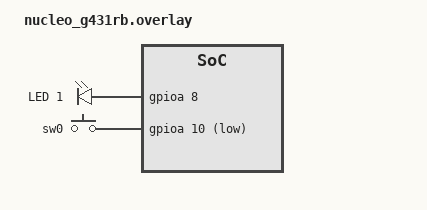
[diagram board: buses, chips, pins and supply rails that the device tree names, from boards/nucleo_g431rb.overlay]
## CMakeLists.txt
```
cmake_minimum_required(VERSION 3.20.0)

set(BOARD stm32f3_disco)

set(CONF_FILE "boards/stm32f3_disco.conf")
list(APPEND CONF_FILE "boards/stm32f3_disco.conf")

find_package(Zephyr REQUIRED HINTS $ENV{ZEPHYR_BASE})
project(se28cp_app)

target_sources(app PRIVATE 
    src/main.h 
    src/led.h 
    src/status.c 
    src/keyboard.h
    src/keyboard.c
    src/adc.c
    src/zbus.c
    src/main.c 
   
)
```

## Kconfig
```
source "Kconfig.zephyr"
config APP_WITH_STM32_HAL
    default y
    bool
    select USE_STM32_HAL_GPIO
    select USE_STM32_HAL_ADC
    select USE_STM32_HAL_ADC_EX
    select USE_STM32_HAL_DAC
    select USE_STM32_HAL_DAC_EX
    select USE_STM32_HAL_DMA
    select USE_STM32_HAL_DMA_EX
    select USE_STM32_HAL_CORTEX
    select USE_STM32_HAL_TIM
    select USE_STM32_HAL_TIM_EX
```

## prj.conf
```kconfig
CONFIG_ASSERT=y
CONFIG_GPIO=y
CONFIG_SHELL=y
```

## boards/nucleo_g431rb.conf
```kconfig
# Misc
CONFIG_HEAP_MEM_POOL_SIZE=8192
CONFIG_SHELL_STACK_SIZE=4096
#CONFIG_SYS_CLOCK_TICKS_PER_SEC=1

# Enable Shell
CONFIG_SHELL=y

# Setting the Shell prompt
CONFIG_SHELL_PROMPT_UART="patchon$ "

# Setting the max argc
CONFIG_SHELL_ARGC_MAX=12

# Enable the Zephyr boot banner
CONFIG_BOOT_BANNER=y

CONFIG_THREAD_RUNTIME_STATS=y

CONFIG_SYS_CLOCK_TICKS_PER_SEC=1000
```

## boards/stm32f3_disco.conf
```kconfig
# Misc
CONFIG_HEAP_MEM_POOL_SIZE=8192
CONFIG_SHELL_STACK_SIZE=4096
#CONFIG_SYS_CLOCK_TICKS_PER_SEC=1

# Enable Shell
CONFIG_SHELL=y

# Setting the Shell prompt
CONFIG_SHELL_PROMPT_UART="patchon$ "

# Setting the max argc
CONFIG_SHELL_ARGC_MAX=12

# Enable the Zephyr boot banner
CONFIG_BOOT_BANNER=y

CONFIG_THREAD_RUNTIME_STATS=y

CONFIG_SYS_CLOCK_TICKS_PER_SEC=1000

CONFIG_ZBUS=y
CONFIG_ZBUS_LOG_LEVEL_INF=y
CONFIG_ZBUS_CHANNEL_NAME=y
CONFIG_ZBUS_OBSERVER_NAME=y
CONFIG_ZBUS_RUNTIME_OBSERVERS=y

CONFIG_CMSIS_DSP=y
CONFIG_NEWLIB_LIBC=y
CONFIG_FPU=y
CONFIG_NEWLIB_LIBC_FLOAT_PRINTF=y
```

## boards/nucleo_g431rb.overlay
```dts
#include <zephyr/dt-bindings/gpio/gpio.h>

/ {
	aliases {
		led1 = &led1;
		sw0 = &sw0;
	};

	leds {
		compatible = "gpio-leds";
		led1: led_1 {
			gpios = <&gpioa 8 GPIO_ACTIVE_HIGH>;
			label = "LED 1";
		};
	};

	buttons {
		compatible = "gpio-keys";
		sw0: sw_0 {
			gpios = <&gpioa 10 (GPIO_PULL_UP | GPIO_ACTIVE_LOW)>;
			zephyr,code = <INPUT_KEY_1>;
		};
	};
};
```

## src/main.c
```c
#include "main.h"

int main(void)
{

	return 0;
}
```

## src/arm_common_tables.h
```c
/* ----------------------------------------------------------------------
 * Copyright (C) 2010-2014 ARM Limited. All rights reserved.
 *
 * $Date:        19. October 2015
 * $Revision: 	V.1.4.5 a
 *
 * Project: 	    CMSIS DSP Library
 * Title:	    arm_common_tables.h
 *
 * Description:	This file has extern declaration for common tables like Bitreverse, reciprocal etc
 * which are used across different functions
 *
 * Target Processor: Cortex-M4/Cortex-M3
 *
 * Redistribution and use in source and binary forms, with or without
 * modification, are permitted provided that the following conditions
 * are met:
 *   - Redistributions of source code must retain the above copyright
 *     notice, this list of conditions and the following disclaimer.
 *   - Redistributions in binary form must reproduce the above copyright
 *     notice, this list of conditions and the following disclaimer in
 *     the documentation and/or other materials provided with the
 *     distribution.
 *   - Neither the name of ARM LIMITED nor the names of its contributors
 *     may be used to endorse or promote products derived from this
 *     software without specific prior written permission.
 *
 * THIS SOFTWARE IS PROVIDED BY THE COPYRIGHT HOLDERS AND CONTRIBUTORS
 * "AS IS" AND ANY EXPRESS OR IMPLIED WARRANTIES, INCLUDING, BUT NOT
 * LIMITED TO, THE IMPLIED WARRANTIES OF MERCHANTABILITY AND FITNESS
 * FOR A PARTICULAR PURPOSE ARE DISCLAIMED. IN NO EVENT SHALL THE
 * COPYRIGHT OWNER OR CONTRIBUTORS BE LIABLE FOR ANY DIRECT, INDIRECT,
 * INCIDENTAL, SPECIAL, EXEMPLARY, OR CONSEQUENTIAL DAMAGES (INCLUDING,
 * BUT NOT LIMITED TO, PROCUREMENT OF SUBSTITUTE GOODS OR SERVICES;
 * LOSS OF USE, DATA, OR PROFITS; OR BUSINESS INTERRUPTION) HOWEVER
 * CAUSED AND ON ANY THEORY OF LIABILITY, WHETHER IN CONTRACT, STRICT
 * LIABILITY, OR TORT (INCLUDING NEGLIGENCE OR OTHERWISE) ARISING IN
 * ANY WAY OUT OF THE USE OF THIS SOFTWARE, EVEN IF ADVISED OF THE
 * POSSIBILITY OF SUCH DAMAGE.
 * -------------------------------------------------------------------- */

#ifndef _ARM_COMMON_TABLES_H
#define _ARM_COMMON_TABLES_H

#include "arm_math.h"

extern const uint16_t armBitRevTable[1024];
extern const q15_t armRecipTableQ15[64];
extern const q31_t armRecipTableQ31[64];
/* extern const q31_t realCoefAQ31[1024]; */
/* extern const q31_t realCoefBQ31[1024]; */
extern const float32_t twiddleCoef_16[32];
extern const float32_t twiddleCoef_32[64];
extern const float32_t twiddleCoef_64[128];
extern const float32_t twiddleCoef_128[256];
extern const float32_t twiddleCoef_256[512];
extern const float32_t twiddleCoef_512[1024];
extern const float32_t twiddleCoef_1024[2048];
extern const float32_t twiddleCoef_2048[4096];
extern const float32_t twiddleCoef_4096[8192];
#define twiddleCoef twiddleCoef_4096
extern const q31_t twiddleCoef_16_q31[24];
extern const q31_t twiddleCoef_32_q31[48];
extern const q31_t twiddleCoef_64_q31[96];
extern const q31_t twiddleCoef_128_q31[192];
extern const q31_t twiddleCoef_256_q31[384];
extern const q31_t twiddleCoef_512_q31[768];
extern const q31_t twiddleCoef_1024_q31[1536];
extern const q31_t twiddleCoef_2048_q31[3072];
extern const q31_t twiddleCoef_4096_q31[6144];
extern const q15_t twiddleCoef_16_q15[24];
extern const q15_t twiddleCoef_32_q15[48];
extern const q15_t twiddleCoef_64_q15[96];
extern const q15_t twiddleCoef_128_q15[192];
extern const q15_t twiddleCoef_256_q15[384];
extern const q15_t twiddleCoef_512_q15[768];
extern const q15_t twiddleCoef_1024_q15[1536];
extern const q15_t twiddleCoef_2048_q15[3072];
extern const q15_t twiddleCoef_4096_q15[6144];
extern const float32_t twiddleCoef_rfft_32[32];
extern const float32_t twiddleCoef_rfft_64[64];
extern const float32_t twiddleCoef_rfft_128[128];
extern const float32_t twiddleCoef_rfft_256[256];
extern const float32_t twiddleCoef_rfft_512[512];
extern const float32_t twiddleCoef_rfft_1024[1024];
extern const float32_t twiddleCoef_rfft_2048[2048];
extern const float32_t twiddleCoef_rfft_4096[4096];

/* floating-point bit reversal tables */
#define ARMBITREVINDEXTABLE__16_TABLE_LENGTH ((uint16_t)20)
#define ARMBITREVINDEXTABLE__32_TABLE_LENGTH ((uint16_t)48)
#define ARMBITREVINDEXTABLE__64_TABLE_LENGTH ((uint16_t)56)
#define ARMBITREVINDEXTABLE_128_TABLE_LENGTH ((uint16_t)208)
#define ARMBITREVINDEXTABLE_256_TABLE_LENGTH ((uint16_t)440)
#define ARMBITREVINDEXTABLE_512_TABLE_LENGTH ((uint16_t)448)
#define ARMBITREVINDEXTABLE1024_TABLE_LENGTH ((uint16_t)1800)
#define ARMBITREVINDEXTABLE2048_TABLE_LENGTH ((uint16_t)3808)
#define ARMBITREVINDEXTABLE4096_TABLE_LENGTH ((uint16_t)4032)

extern const uint16_t armBitRevIndexTable16[ARMBITREVINDEXTABLE__16_TABLE_LENGTH];
extern const uint16_t armBitRevIndexTable32[ARMBITREVINDEXTABLE__32_TABLE_LENGTH];
extern const uint16_t armBitRevIndexTable64[ARMBITREVINDEXTABLE__64_TABLE_LENGTH];
extern const uint16_t armBitRevIndexTable128[ARMBITREVINDEXTABLE_128_TABLE_LENGTH];
extern const uint16_t armBitRevIndexTable256[ARMBITREVINDEXTABLE_256_TABLE_LENGTH];
extern const uint16_t armBitRevIndexTable512[ARMBITREVINDEXTABLE_512_TABLE_LENGTH];
extern const uint16_t armBitRevIndexTable1024[ARMBITREVINDEXTABLE1024_TABLE_LENGTH];
extern const uint16_t armBitRevIndexTable2048[ARMBITREVINDEXTABLE2048_TABLE_LENGTH];
extern const uint16_t armBitRevIndexTable4096[ARMBITREVINDEXTABLE4096_TABLE_LENGTH];

/* fixed-point bit reversal tables */
#define ARMBITREVINDEXTABLE_FIXED___16_TABLE_LENGTH ((uint16_t)12)
#define ARMBITREVINDEXTABLE_FIXED___32_TABLE_LENGTH ((uint16_t)24)
#define ARMBITREVINDEXTABLE_FIXED___64_TABLE_LENGTH ((uint16_t)56)
#define ARMBITREVINDEXTABLE_FIXED__128_TABLE_LENGTH ((uint16_t)112)
#define ARMBITREVINDEXTABLE_FIXED__256_TABLE_LENGTH ((uint16_t)240)
#define ARMBITREVINDEXTABLE_FIXED__512_TABLE_LENGTH ((uint16_t)480)
#define ARMBITREVINDEXTABLE_FIXED_1024_TABLE_LENGTH ((uint16_t)992)
#define ARMBITREVINDEXTABLE_FIXED_2048_TABLE_LENGTH ((uint16_t)1984)
#define ARMBITREVINDEXTABLE_FIXED_4096_TABLE_LENGTH ((uint16_t)4032)

extern const uint16_t armBitRevIndexTable_fixed_16[ARMBITREVINDEXTABLE_FIXED___16_TABLE_LENGTH];
extern const uint16_t armBitRevIndexTable_fixed_32[ARMBITREVINDEXTABLE_FIXED___32_TABLE_LENGTH];
extern const uint16_t armBitRevIndexTable_fixed_64[ARMBITREVINDEXTABLE_FIXED___64_TABLE_LENGTH];
extern const uint16_t armBitRevIndexTable_fixed_128[ARMBITREVINDEXTABLE_FIXED__128_TABLE_LENGTH];
extern const uint16_t armBitRevIndexTable_fixed_256[ARMBITREVINDEXTABLE_FIXED__256_TABLE_LENGTH];
extern const uint16_t armBitRevIndexTable_fixed_512[ARMBITREVINDEXTABLE_FIXED__512_TABLE_LENGTH];
extern const uint16_t armBitRevIndexTable_fixed_1024[ARMBITREVINDEXTABLE_FIXED_1024_TABLE_LENGTH];
extern const uint16_t armBitRevIndexTable_fixed_2048[ARMBITREVINDEXTABLE_FIXED_2048_TABLE_LENGTH];
extern const uint16_t armBitRevIndexTable_fixed_4096[ARMBITREVINDEXTABLE_FIXED_4096_TABLE_LENGTH];

/* Tables for Fast Math Sine and Cosine */
extern const float32_t sinTable_f32[FAST_MATH_TABLE_SIZE + 1];
extern const q31_t sinTable_q31[FAST_MATH_TABLE_SIZE + 1];
extern const q15_t sinTable_q15[FAST_MATH_TABLE_SIZE + 1];

#endif /*  ARM_COMMON_TABLES_H */
```

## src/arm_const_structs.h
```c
/* ----------------------------------------------------------------------
 * Copyright (C) 2010-2014 ARM Limited. All rights reserved.
 *
 * $Date:        19. March 2015
 * $Revision: 	V.1.4.5
 *
 * Project: 	    CMSIS DSP Library
 * Title:	    arm_const_structs.h
 *
 * Description:	This file has constant structs that are initialized for
 *              user convenience.  For example, some can be given as
 *              arguments to the arm_cfft_f32() function.
 *
 * Target Processor: Cortex-M4/Cortex-M3
 *
 * Redistribution and use in source and binary forms, with or without
 * modification, are permitted provided that the following conditions
 * are met:
 *   - Redistributions of source code must retain the above copyright
 *     notice, this list of conditions and the following disclaimer.
 *   - Redistributions in binary form must reproduce the above copyright
 *     notice, this list of conditions and the following disclaimer in
 *     the documentation and/or other materials provided with the
 *     distribution.
 *   - Neither the name of ARM LIMITED nor the names of its contributors
 *     may be used to endorse or promote products derived from this
 *     software without specific prior written permission.
 *
 * THIS SOFTWARE IS PROVIDED BY THE COPYRIGHT HOLDERS AND CONTRIBUTORS
 * "AS IS" AND ANY EXPRESS OR IMPLIED WARRANTIES, INCLUDING, BUT NOT
 * LIMITED TO, THE IMPLIED WARRANTIES OF MERCHANTABILITY AND FITNESS
 * FOR A PARTICULAR PURPOSE ARE DISCLAIMED. IN NO EVENT SHALL THE
 * COPYRIGHT OWNER OR CONTRIBUTORS BE LIABLE FOR ANY DIRECT, INDIRECT,
 * INCIDENTAL, SPECIAL, EXEMPLARY, OR CONSEQUENTIAL DAMAGES (INCLUDING,
 * BUT NOT LIMITED TO, PROCUREMENT OF SUBSTITUTE GOODS OR SERVICES;
 * LOSS OF USE, DATA, OR PROFITS; OR BUSINESS INTERRUPTION) HOWEVER
 * CAUSED AND ON ANY THEORY OF LIABILITY, WHETHER IN CONTRACT, STRICT
 * LIABILITY, OR TORT (INCLUDING NEGLIGENCE OR OTHERWISE) ARISING IN
 * ANY WAY OUT OF THE USE OF THIS SOFTWARE, EVEN IF ADVISED OF THE
 * POSSIBILITY OF SUCH DAMAGE.
 * -------------------------------------------------------------------- */

#ifndef _ARM_CONST_STRUCTS_H
#define _ARM_CONST_STRUCTS_H

#include "arm_math.h"
#include "arm_common_tables.h"

extern const arm_cfft_instance_f32 arm_cfft_sR_f32_len16;
extern const arm_cfft_instance_f32 arm_cfft_sR_f32_len32;
extern const arm_cfft_instance_f32 arm_cfft_sR_f32_len64;
extern const arm_cfft_instance_f32 arm_cfft_sR_f32_len128;
extern const arm_cfft_instance_f32 arm_cfft_sR_f32_len256;
extern const arm_cfft_instance_f32 arm_cfft_sR_f32_len512;
extern const arm_cfft_instance_f32 arm_cfft_sR_f32_len1024;
extern const arm_cfft_instance_f32 arm_cfft_sR_f32_len2048;
extern const arm_cfft_instance_f32 arm_cfft_sR_f32_len4096;

extern const arm_cfft_instance_q31 arm_cfft_sR_q31_len16;
extern const arm_cfft_instance_q31 arm_cfft_sR_q31_len32;
extern const arm_cfft_instance_q31 arm_cfft_sR_q31_len64;
extern const arm_cfft_instance_q31 arm_cfft_sR_q31_len128;
extern const arm_cfft_instance_q31 arm_cfft_sR_q31_len256;
extern const arm_cfft_instance_q31 arm_cfft_sR_q31_len512;
extern const arm_cfft_instance_q31 arm_cfft_sR_q31_len1024;
extern const arm_cfft_instance_q31 arm_cfft_sR_q31_len2048;
extern const arm_cfft_instance_q31 arm_cfft_sR_q31_len4096;

extern const arm_cfft_instance_q15 arm_cfft_sR_q15_len16;
extern const arm_cfft_instance_q15 arm_cfft_sR_q15_len32;
extern const arm_cfft_instance_q15 arm_cfft_sR_q15_len64;
extern const arm_cfft_instance_q15 arm_cfft_sR_q15_len128;
extern const arm_cfft_instance_q15 arm_cfft_sR_q15_len256;
extern const arm_cfft_instance_q15 arm_cfft_sR_q15_len512;
extern const arm_cfft_instance_q15 arm_cfft_sR_q15_len1024;
extern const arm_cfft_instance_q15 arm_cfft_sR_q15_len2048;
extern const arm_cfft_instance_q15 arm_cfft_sR_q15_len4096;

#endif
```

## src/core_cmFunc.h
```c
/**************************************************************************/ /**
									      * @file core_cmFunc.h
									      * @brief    CMSIS
									      *Cortex-M Core
									      *Function Access
									      *Header File
									      * @version  V4.30
									      * @date     20.
									      *October 2015
									      ******************************************************************************/
/* Copyright (c) 2009 - 2015 ARM LIMITED

   All rights reserved.
   Redistribution and use in source and binary forms, with or without
   modification, are permitted provided that the following conditions are met:
   - Redistributions of source code must retain the above copyright
     notice, this list of conditions and the following disclaimer.
   - Redistributions in binary form must reproduce the above copyright
     notice, this list of conditions and the following disclaimer in the
     documentation and/or other materials provided with the distribution.
   - Neither the name of ARM nor the names of its contributors may be used
     to endorse or promote products derived from this software without
     specific prior written permission.
   *
   THIS SOFTWARE IS PROVIDED BY THE COPYRIGHT HOLDERS AND CONTRIBUTORS "AS IS"
   AND ANY EXPRESS OR IMPLIED WARRANTIES, INCLUDING, BUT NOT LIMITED TO, THE
   IMPLIED WARRANTIES OF MERCHANTABILITY AND FITNESS FOR A PARTICULAR PURPOSE
   ARE DISCLAIMED. IN NO EVENT SHALL COPYRIGHT HOLDERS AND CONTRIBUTORS BE
   LIABLE FOR ANY DIRECT, INDIRECT, INCIDENTAL, SPECIAL, EXEMPLARY, OR
   CONSEQUENTIAL DAMAGES (INCLUDING, BUT NOT LIMITED TO, PROCUREMENT OF
   SUBSTITUTE GOODS OR SERVICES; LOSS OF USE, DATA, OR PROFITS; OR BUSINESS
   INTERRUPTION) HOWEVER CAUSED AND ON ANY THEORY OF LIABILITY, WHETHER IN
   CONTRACT, STRICT LIABILITY, OR TORT (INCLUDING NEGLIGENCE OR OTHERWISE)
   ARISING IN ANY WAY OUT OF THE USE OF THIS SOFTWARE, EVEN IF ADVISED OF THE
   POSSIBILITY OF SUCH DAMAGE.
   ---------------------------------------------------------------------------*/

#if defined(__ICCARM__)
#pragma system_include /* treat file as system include file for MISRA check */
#elif defined(__ARMCC_VERSION) && (__ARMCC_VERSION >= 6010050)
#pragma clang system_header /* treat file as system include file */
#endif

#ifndef __CORE_CMFUNC_H
#define __CORE_CMFUNC_H

/* ###########################  Core Function Access  ########################### */
/** \ingroup  CMSIS_Core_FunctionInterface
    \defgroup CMSIS_Core_RegAccFunctions CMSIS Core Register Access Functions
  @{
*/

/*------------------ RealView Compiler -----------------*/
#if defined(__CC_ARM)
#include "cmsis_armcc.h"

/*------------------ ARM Compiler V6 -------------------*/
#elif defined(__ARMCC_VERSION) && (__ARMCC_VERSION >= 6010050)
#include "cmsis_armcc_V6.h"

/*------------------ GNU Compiler ----------------------*/
#elif defined(__GNUC__)
#include "cmsis_gcc.h"

/*------------------ ICC Compiler ----------------------*/
#elif defined(__ICCARM__)
#include <cmsis_iar.h>

/*------------------ TI CCS Compiler -------------------*/
#elif defined(__TMS470__)
#include <cmsis_ccs.h>

/*------------------ TASKING Compiler ------------------*/
#elif defined(__TASKING__)
/*
 * The CMSIS functions have been implemented as intrinsics in the compiler.
 * Please use "carm -?i" to get an up to date list of all intrinsics,
 * Including the CMSIS ones.
 */

/*------------------ COSMIC Compiler -------------------*/
#elif defined(__CSMC__)
#include <cmsis_csm.h>

#endif

/*@} end of CMSIS_Core_RegAccFunctions */

#endif /* __CORE_CMFUNC_H */
```

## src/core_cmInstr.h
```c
/**************************************************************************/ /**
									      * @file core_cmInstr.h
									      * @brief    CMSIS
									      *Cortex-M Core
									      *Instruction Access
									      *Header File
									      * @version  V4.30
									      * @date     20.
									      *October 2015
									      ******************************************************************************/
/* Copyright (c) 2009 - 2015 ARM LIMITED

   All rights reserved.
   Redistribution and use in source and binary forms, with or without
   modification, are permitted provided that the following conditions are met:
   - Redistributions of source code must retain the above copyright
     notice, this list of conditions and the following disclaimer.
   - Redistributions in binary form must reproduce the above copyright
     notice, this list of conditions and the following disclaimer in the
     documentation and/or other materials provided with the distribution.
   - Neither the name of ARM nor the names of its contributors may be used
     to endorse or promote products derived from this software without
     specific prior written permission.
   *
   THIS SOFTWARE IS PROVIDED BY THE COPYRIGHT HOLDERS AND CONTRIBUTORS "AS IS"
   AND ANY EXPRESS OR IMPLIED WARRANTIES, INCLUDING, BUT NOT LIMITED TO, THE
   IMPLIED WARRANTIES OF MERCHANTABILITY AND FITNESS FOR A PARTICULAR PURPOSE
   ARE DISCLAIMED. IN NO EVENT SHALL COPYRIGHT HOLDERS AND CONTRIBUTORS BE
   LIABLE FOR ANY DIRECT, INDIRECT, INCIDENTAL, SPECIAL, EXEMPLARY, OR
   CONSEQUENTIAL DAMAGES (INCLUDING, BUT NOT LIMITED TO, PROCUREMENT OF
   SUBSTITUTE GOODS OR SERVICES; LOSS OF USE, DATA, OR PROFITS; OR BUSINESS
   INTERRUPTION) HOWEVER CAUSED AND ON ANY THEORY OF LIABILITY, WHETHER IN
   CONTRACT, STRICT LIABILITY, OR TORT (INCLUDING NEGLIGENCE OR OTHERWISE)
   ARISING IN ANY WAY OUT OF THE USE OF THIS SOFTWARE, EVEN IF ADVISED OF THE
   POSSIBILITY OF SUCH DAMAGE.
   ---------------------------------------------------------------------------*/

#if defined(__ICCARM__)
#pragma system_include /* treat file as system include file for MISRA check */
#elif defined(__ARMCC_VERSION) && (__ARMCC_VERSION >= 6010050)
#pragma clang system_header /* treat file as system include file */
#endif

#ifndef __CORE_CMINSTR_H
#define __CORE_CMINSTR_H

/* ##########################  Core Instruction Access  ######################### */
/** \defgroup CMSIS_Core_InstructionInterface CMSIS Core Instruction Interface
  Access to dedicated instructions
  @{
*/

/*------------------ RealView Compiler -----------------*/
#if defined(__CC_ARM)
#include "cmsis_armcc.h"

/*------------------ ARM Compiler V6 -------------------*/
#elif defined(__ARMCC_VERSION) && (__ARMCC_VERSION >= 6010050)
#include "cmsis_armcc_V6.h"

/*------------------ GNU Compiler ----------------------*/
#elif defined(__GNUC__)
#include "cmsis_gcc.h"

/*------------------ ICC Compiler ----------------------*/
#elif defined(__ICCARM__)
#include <cmsis_iar.h>

/*------------------ TI CCS Compiler -------------------*/
#elif defined(__TMS470__)
#include <cmsis_ccs.h>

/*------------------ TASKING Compiler ------------------*/
#elif defined(__TASKING__)
/*
 * The CMSIS functions have been implemented as intrinsics in the compiler.
 * Please use "carm -?i" to get an up to date list of all intrinsics,
 * Including the CMSIS ones.
 */

/*------------------ COSMIC Compiler -------------------*/
#elif defined(__CSMC__)
#include <cmsis_csm.h>

#endif

/*@}*/ /* end of group CMSIS_Core_InstructionInterface */

#endif /* __CORE_CMINSTR_H */
```

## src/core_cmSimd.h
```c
/**************************************************************************/ /**
									      * @file core_cmSimd.h
									      * @brief    CMSIS
									      *Cortex-M SIMD Header
									      *File
									      * @version  V4.30
									      * @date     20.
									      *October 2015
									      ******************************************************************************/
/* Copyright (c) 2009 - 2015 ARM LIMITED

   All rights reserved.
   Redistribution and use in source and binary forms, with or without
   modification, are permitted provided that the following conditions are met:
   - Redistributions of source code must retain the above copyright
     notice, this list of conditions and the following disclaimer.
   - Redistributions in binary form must reproduce the above copyright
     notice, this list of conditions and the following disclaimer in the
     documentation and/or other materials provided with the distribution.
   - Neither the name of ARM nor the names of its contributors may be used
     to endorse or promote products derived from this software without
     specific prior written permission.
   *
   THIS SOFTWARE IS PROVIDED BY THE COPYRIGHT HOLDERS AND CONTRIBUTORS "AS IS"
   AND ANY EXPRESS OR IMPLIED WARRANTIES, INCLUDING, BUT NOT LIMITED TO, THE
   IMPLIED WARRANTIES OF MERCHANTABILITY AND FITNESS FOR A PARTICULAR PURPOSE
   ARE DISCLAIMED. IN NO EVENT SHALL COPYRIGHT HOLDERS AND CONTRIBUTORS BE
   LIABLE FOR ANY DIRECT, INDIRECT, INCIDENTAL, SPECIAL, EXEMPLARY, OR
   CONSEQUENTIAL DAMAGES (INCLUDING, BUT NOT LIMITED TO, PROCUREMENT OF
   SUBSTITUTE GOODS OR SERVICES; LOSS OF USE, DATA, OR PROFITS; OR BUSINESS
   INTERRUPTION) HOWEVER CAUSED AND ON ANY THEORY OF LIABILITY, WHETHER IN
   CONTRACT, STRICT LIABILITY, OR TORT (INCLUDING NEGLIGENCE OR OTHERWISE)
   ARISING IN ANY WAY OUT OF THE USE OF THIS SOFTWARE, EVEN IF ADVISED OF THE
   POSSIBILITY OF SUCH DAMAGE.
   ---------------------------------------------------------------------------*/

#if defined(__ICCARM__)
#pragma system_include /* treat file as system include file for MISRA check */
#elif defined(__ARMCC_VERSION) && (__ARMCC_VERSION >= 6010050)
#pragma clang system_header /* treat file as system include file */
#endif

#ifndef __CORE_CMSIMD_H
#define __CORE_CMSIMD_H

#ifdef __cplusplus
extern "C" {
#endif

/* ###################  Compiler specific Intrinsics  ########################### */
/** \defgroup CMSIS_SIMD_intrinsics CMSIS SIMD Intrinsics
  Access to dedicated SIMD instructions
  @{
*/

/*------------------ RealView Compiler -----------------*/
#if defined(__CC_ARM)
#include "cmsis_armcc.h"

/*------------------ ARM Compiler V6 -------------------*/
#elif defined(__ARMCC_VERSION) && (__ARMCC_VERSION >= 6010050)
#include "cmsis_armcc_V6.h"

/*------------------ GNU Compiler ----------------------*/
#elif defined(__GNUC__)
#include "cmsis_gcc.h"

/*------------------ ICC Compiler ----------------------*/
#elif defined(__ICCARM__)
#include <cmsis_iar.h>

/*------------------ TI CCS Compiler -------------------*/
#elif defined(__TMS470__)
#include <cmsis_ccs.h>

/*------------------ TASKING Compiler ------------------*/
#elif defined(__TASKING__)
/*
 * The CMSIS functions have been implemented as intrinsics in the compiler.
 * Please use "carm -?i" to get an up to date list of all intrinsics,
 * Including the CMSIS ones.
 */

/*------------------ COSMIC Compiler -------------------*/
#elif defined(__CSMC__)
#include <cmsis_csm.h>

#endif

/*@} end of group CMSIS_SIMD_intrinsics */

#ifdef __cplusplus
}
#endif

#endif /* __CORE_CMSIMD_H */
```

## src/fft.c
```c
#include <stdio.h>
#include <stdlib.h>
#include <string.h>

#include "stm32f3xx_hal.c"

ADC_HandleTypeDef hadc1;
DMA_HandleTypeDef hdma_adc1;

DAC_HandleTypeDef hdac1;
DMA_HandleTypeDef hdma_dac1_ch1;

UART_HandleTypeDef hlpuart1;

TIM_HandleTypeDef htim2;
TIM_HandleTypeDef htim3;
TIM_HandleTypeDef htim8;

/* USER CODE BEGIN PV */

/* USER CODE END PV */

/* Private function prototypes -----------------------------------------------*/
void SystemClock_Config(void);
static void MX_GPIO_Init(void);
static void MX_DMA_Init(void);
static void MX_LPUART1_UART_Init(void);
static void MX_TIM2_Init(void);
static void MX_DAC1_Init(void);
static void MX_ADC1_Init(void);
static void MX_TIM3_Init(void);
static void MX_TIM8_Init(void);
void StartDefaultTask(void const *argument);

/* USER CODE BEGIN PFP */

uint16_t adcBuffer[256];
float ReIm[256 * 2];
float mod[256];

uint16_t sin_wave[256];
uint16_t sin_wave_3rd_harmonic[256];
static BaseType_t prvTaskDACCommand(char *pcWriteBuffer, size_t xWriteBufferLen,
				    const char *pcCommandString)
{
	// BaseType_t parameter_lenght;
	// const char *parameter = FreeRTOS_CLIGetParameter(pcCommandString, 1, &parameter_lenght);

	// pegar os parametros do shell
	char parameter[] = {"s,i,n,e"};

	if (!strcmp(parameter, "sine")) {
		HAL_TIM_Base_Stop(&htim2);
		HAL_DAC_Stop_DMA(&hdac1, DAC_CHANNEL_1);
		HAL_DAC_Start_DMA(&hdac1, DAC_CHANNEL_1, (uint32_t *)sin_wave, 256,
				  DAC_ALIGN_12B_R);
		HAL_TIM_Base_Start(&htim2);
		strcpy(pcWriteBuffer, "Sine set for the DAC signal\n\r");
	} else if (!strcmp(parameter, "sine3rd")) {
		HAL_TIM_Base_Stop(&htim2);
		HAL_DAC_Stop_DMA(&hdac1, DAC_CHANNEL_1);
		HAL_DAC_Start_DMA(&hdac1, DAC_CHANNEL_1, (uint32_t *)sin_wave_3rd_harmonic, 256,
				  DAC_ALIGN_12B_R);
		HAL_TIM_Base_Start(&htim2);
		strcpy(pcWriteBuffer, "Sine 3rd harmonic set for the DAC signal\n\r");
	} else {
		strcpy(pcWriteBuffer, "Not a valid DAC signal!\n\r");
	}
	return pdFALSE;
}

static BaseType_t prvTaskFFTCommand(char *pcWriteBuffer, size_t xWriteBufferLen,
				    const char *pcCommandString)
{
	// BaseType_t parameter_lenght;
	// const char *parameter1 = FreeRTOS_CLIGetParameter(pcCommandString, 1, &parameter_lenght);
	// const char *parameter2 = FreeRTOS_CLIGetParameter(pcCommandString, 2, &parameter_lenght);

	// pegar os argumentos do shell

	int first_harm = atoi(parameter1);
	int number_harm = atoi(parameter2);

	if ((first_harm >= 0) && (number_harm > 0)) {
		int len = sprintf(pcWriteBuffer,
				  "FFT result for the current DAC signal (%d, %d): ", first_harm,
				  number_harm);
		for (int i = first_harm; i < (number_harm + first_harm); i++) {
			if (i == 0) {
				len += sprintf(&pcWriteBuffer[len], "%f ", mod[i] / 2.0);
			} else {
				len += sprintf(&pcWriteBuffer[len], "%f ", mod[i]);
			}
		}
		sprintf(&pcWriteBuffer[len], "\n\r");
	} else {
		strcpy(pcWriteBuffer, "Invalid parameters!\n\r");
	}

	return pdFALSE;
}

#define cmdPARAMTER_NOT_USED ((void *)0)
#define MAX_INPUT_LENGTH     50
#define MAX_OUTPUT_LENGTH    512

uint16_t sin_wave[256] = {
	2048, 2098, 2148, 2199, 2249, 2299, 2349, 2399, 2448, 2498, 2547, 2596, 2644, 2692, 2740,
	2787, 2834, 2880, 2926, 2971, 3016, 3060, 3104, 3147, 3189, 3230, 3271, 3311, 3351, 3389,
	3427, 3464, 3500, 3535, 3569, 3602, 3635, 3666, 3697, 3726, 3754, 3782, 3808, 3833, 3857,
	3880, 3902, 3923, 3943, 3961, 3979, 3995, 4010, 4024, 4036, 4048, 4058, 4067, 4074, 4081,
	4086, 4090, 4093, 4095, 4095, 4094, 4092, 4088, 4084, 4078, 4071, 4062, 4053, 4042, 4030,
	4017, 4002, 3987, 3970, 3952, 3933, 3913, 3891, 3869, 3845, 3821, 3795, 3768, 3740, 3711,
	3681, 3651, 3619, 3586, 3552, 3517, 3482, 3445, 3408, 3370, 3331, 3291, 3251, 3210, 3168,
	3125, 3082, 3038, 2994, 2949, 2903, 2857, 2811, 2764, 2716, 2668, 2620, 2571, 2522, 2473,
	2424, 2374, 2324, 2274, 2224, 2174, 2123, 2073, 2022, 1972, 1921, 1871, 1821, 1771, 1721,
	1671, 1622, 1573, 1524, 1475, 1427, 1379, 1331, 1284, 1238, 1192, 1146, 1101, 1057, 1013,
	970,  927,  885,  844,  804,  764,  725,  687,  650,  613,  578,  543,  509,  476,  444,
	414,  384,  355,  327,  300,  274,  250,  226,  204,  182,  162,  143,  125,  108,  93,
	78,   65,   53,   42,   33,   24,   17,   11,   7,    3,    1,    0,    0,    2,    5,
	9,    14,   21,   28,   37,   47,   59,   71,   85,   100,  116,  134,  152,  172,  193,
	215,  238,  262,  287,  313,  341,  369,  398,  429,  460,  493,  526,  560,  595,  631,
	668,  706,  744,  784,  824,  865,  906,  948,  991,  1035, 1079, 1124, 1169, 1215, 1261,
	1308, 1355, 1403, 1451, 1499, 1548, 1597, 1647, 1696, 1746, 1796, 1846, 1896, 1947, 1997,
	2047};

uint16_t sin_wave_3rd_harmonic[256] = {
	2048, 2136, 2224, 2311, 2398, 2484, 2569, 2652, 2734, 2814, 2892, 2968, 3041, 3112, 3180,
	3245, 3308, 3367, 3423, 3476, 3526, 3572, 3615, 3654, 3690, 3723, 3752, 3778, 3800, 3819,
	3835, 3848, 3858, 3866, 3870, 3872, 3871, 3869, 3864, 3857, 3848, 3838, 3827, 3814, 3801,
	3786, 3771, 3756, 3740, 3725, 3709, 3694, 3679, 3665, 3652, 3639, 3628, 3617, 3608, 3600,
	3594, 3589, 3585, 3584, 3583, 3584, 3587, 3591, 3597, 3604, 3613, 3622, 3633, 3645, 3658,
	3672, 3686, 3701, 3717, 3732, 3748, 3764, 3779, 3794, 3808, 3821, 3833, 3844, 3853, 3860,
	3866, 3870, 3872, 3871, 3868, 3862, 3854, 3842, 3828, 3810, 3789, 3765, 3738, 3707, 3673,
	3635, 3594, 3549, 3501, 3450, 3396, 3338, 3277, 3213, 3146, 3077, 3005, 2930, 2853, 2774,
	2693, 2611, 2527, 2441, 2355, 2268, 2180, 2092, 2003, 1915, 1827, 1740, 1654, 1568, 1484,
	1402, 1321, 1242, 1165, 1090, 1018, 949,  882,  818,  757,  699,  645,  594,  546,  501,
	460,  422,  388,  357,  330,  306,  285,  267,  253,  241,  233,  227,  224,  223,  225,
	229,  235,  242,  251,  262,  274,  287,  301,  316,  331,  347,  363,  378,  394,  409,
	423,  437,  450,  462,  473,  482,  491,  498,  504,  508,  511,  512,  511,  510,  506,
	501,  495,  487,  478,  467,  456,  443,  430,  416,  401,  386,  370,  355,  339,  324,
	309,  294,  281,  268,  257,  247,  238,  231,  226,  224,  223,  225,  229,  237,  247,
	260,  276,  295,  317,  343,  372,  405,  441,  480,  523,  569,  619,  672,  728,  787,
	850,  915,  983,  1054, 1127, 1203, 1281, 1361, 1443, 1526, 1611, 1697, 1784, 1871, 1959,
	2047};

void HAL_ADC_ConvCpltCallback(ADC_HandleTypeDef *hadc)
{
	portBASE_TYPE pxHigherPriorityTaskWoken = pdFALSE;
	xSemaphoreGiveFromISR(sem_adc, &pxHigherPriorityTaskWoken);
	portYIELD_FROM_ISR(pxHigherPriorityTaskWoken);
}

void adc_task(void *param)
{
	HAL_ADC_Start_DMA(&hadc1, (uint32_t *)adcBuffer, 256);
	HAL_DAC_Start_DMA(&hdac1, DAC_CHANNEL_1, (uint32_t *)sin_wave_3rd_harmonic, 256,
			  DAC_ALIGN_12B_R);

	HAL_TIM_Base_Start(&htim8);
	HAL_TIM_Base_Start(&htim3);

	while (1) {
		xSemaphoreTake(sem_adc, portMAX_DELAY);

		int k = 0;
		for (int i = 0; i < 256; i++) {
			ReIm[k] = (float)adcBuffer[i] * 0.0008056640625;
			ReIm[k + 1] = 0.0;
			k += 2;
		}

		arm_cfft_f32(&arm_cfft_sR_f32_len256, ReIm, 0, 1);
		arm_cmplx_mag_f32(ReIm, mod, 256);
		arm_scale_f32(mod, 0.0078125, mod, 128);

		volatile float fund_phase =
			atan2f(ReIm[3], ReIm[2]) * 180 / M_PI; // Fase R da harmonica fundamental
		(void)fund_phase;
	}
}

int main(void)
{
	HAL_Init();
	SystemClock_Config();
	MX_GPIO_Init();
	MX_DMA_Init();
	MX_LPUART1_UART_Init();
	MX_TIM2_Init();
	MX_DAC1_Init();
	MX_ADC1_Init();
	MX_TIM3_Init();
	MX_TIM8_Init();

	xTaskCreate(adc_task, "ADC Task", 512, NULL, 6, NULL);
	osKernelStart();

	while (1) {
	}
}

void SystemClock_Config(void)
{
	RCC_OscInitTypeDef RCC_OscInitStruct = {0};
	RCC_ClkInitTypeDef RCC_ClkInitStruct = {0};
	HAL_PWREx_ControlVoltageScaling(PWR_REGULATOR_VOLTAGE_SCALE1_BOOST);
	RCC_OscInitStruct.OscillatorType = RCC_OSCILLATORTYPE_HSE;
	RCC_OscInitStruct.HSEState = RCC_HSE_ON;
	RCC_OscInitStruct.PLL.PLLState = RCC_PLL_ON;
	RCC_OscInitStruct.PLL.PLLSource = RCC_PLLSOURCE_HSE;
	RCC_OscInitStruct.PLL.PLLM = RCC_PLLM_DIV6;
	RCC_OscInitStruct.PLL.PLLN = 85;
	RCC_OscInitStruct.PLL.PLLP = RCC_PLLP_DIV2;
	RCC_OscInitStruct.PLL.PLLQ = RCC_PLLQ_DIV2;
	RCC_OscInitStruct.PLL.PLLR = RCC_PLLR_DIV2;
	if (HAL_RCC_OscConfig(&RCC_OscInitStruct) != HAL_OK) {
		Error_Handler();
	}

	/** Initializes the CPU, AHB and APB buses clocks
	 */
	RCC_ClkInitStruct.ClockType = RCC_CLOCKTYPE_HCLK | RCC_CLOCKTYPE_SYSCLK |
				      RCC_CLOCKTYPE_PCLK1 | RCC_CLOCKTYPE_PCLK2;
	RCC_ClkInitStruct.SYSCLKSource = RCC_SYSCLKSOURCE_PLLCLK;
	RCC_ClkInitStruct.AHBCLKDivider = RCC_SYSCLK_DIV1;
	RCC_ClkInitStruct.APB1CLKDivider = RCC_HCLK_DIV1;
	RCC_ClkInitStruct.APB2CLKDivider = RCC_HCLK_DIV1;

	if (HAL_RCC_ClockConfig(&RCC_ClkInitStruct, FLASH_LATENCY_4) != HAL_OK) {
		Error_Handler();
	}
}

static void MX_ADC1_Init(void)
{
	ADC_MultiModeTypeDef multimode = {0};
	ADC_ChannelConfTypeDef sConfig = {0};
	hadc1.Instance = ADC1;
	hadc1.Init.ClockPrescaler = ADC_CLOCK_SYNC_PCLK_DIV4;
	hadc1.Init.Resolution = ADC_RESOLUTION_12B;
	hadc1.Init.DataAlign = ADC_DATAALIGN_RIGHT;
	hadc1.Init.GainCompensation = 0;
	hadc1.Init.ScanConvMode = ADC_SCAN_DISABLE;
	hadc1.Init.EOCSelection = ADC_EOC_SINGLE_CONV;
	hadc1.Init.LowPowerAutoWait = DISABLE;
	hadc1.Init.ContinuousConvMode = DISABLE;
	hadc1.Init.NbrOfConversion = 1;
	hadc1.Init.DiscontinuousConvMode = DISABLE;
	hadc1.Init.ExternalTrigConv = ADC_EXTERNALTRIG_T8_TRGO;
	hadc1.Init.ExternalTrigConvEdge = ADC_EXTERNALTRIGCONVEDGE_RISING;
	hadc1.Init.DMAContinuousRequests = ENABLE;
	hadc1.Init.Overrun = ADC_OVR_DATA_PRESERVED;
	hadc1.Init.OversamplingMode = DISABLE;
	if (HAL_ADC_Init(&hadc1) != HAL_OK) {
		Error_Handler();
	}

	multimode.Mode = ADC_MODE_INDEPENDENT;
	if (HAL_ADCEx_MultiModeConfigChannel(&hadc1, &multimode) != HAL_OK) {
		Error_Handler();
	}
	sConfig.Channel = ADC_CHANNEL_1;
	sConfig.Rank = ADC_REGULAR_RANK_1;
	sConfig.SamplingTime = ADC_SAMPLETIME_2CYCLES_5;
	sConfig.SingleDiff = ADC_SINGLE_ENDED;
	sConfig.OffsetNumber = ADC_OFFSET_NONE;
	sConfig.Offset = 0;
	if (HAL_ADC_ConfigChannel(&hadc1, &sConfig) != HAL_OK) {
		Error_Handler();
	}
}

static void MX_DAC1_Init(void)
{
	DAC_ChannelConfTypeDef sConfig = {0};
	hdac1.Instance = DAC1;
	if (HAL_DAC_Init(&hdac1) != HAL_OK) {
		Error_Handler();
	}
	sConfig.DAC_HighFrequency = DAC_HIGH_FREQUENCY_INTERFACE_MODE_AUTOMATIC;
	sConfig.DAC_DMADoubleDataMode = DISABLE;
	sConfig.DAC_SignedFormat = DISABLE;
	sConfig.DAC_SampleAndHold = DAC_SAMPLEANDHOLD_DISABLE;
	sConfig.DAC_Trigger = DAC_TRIGGER_T3_TRGO;
	sConfig.DAC_Trigger2 = DAC_TRIGGER_NONE;
	sConfig.DAC_OutputBuffer = DAC_OUTPUTBUFFER_ENABLE;
	sConfig.DAC_ConnectOnChipPeripheral = DAC_CHIPCONNECT_EXTERNAL;
	sConfig.DAC_UserTrimming = DAC_TRIMMING_FACTORY;
	if (HAL_DAC_ConfigChannel(&hdac1, &sConfig, DAC_CHANNEL_1) != HAL_OK) {
		Error_Handler();
	}
}

static void MX_LPUART1_UART_Init(void)
{
	hlpuart1.Instance = LPUART1;
	hlpuart1.Init.BaudRate = 115200;
	hlpuart1.Init.WordLength = UART_WORDLENGTH_8B;
	hlpuart1.Init.StopBits = UART_STOPBITS_1;
	hlpuart1.Init.Parity = UART_PARITY_NONE;
	hlpuart1.Init.Mode = UART_MODE_TX_RX;
	hlpuart1.Init.HwFlowCtl = UART_HWCONTROL_NONE;
	hlpuart1.Init.OneBitSampling = UART_ONE_BIT_SAMPLE_DISABLE;
	hlpuart1.Init.ClockPrescaler = UART_PRESCALER_DIV1;
	hlpuart1.AdvancedInit.AdvFeatureInit = UART_ADVFEATURE_NO_INIT;
	if (HAL_UART_Init(&hlpuart1) != HAL_OK) {
		Error_Handler();
	}
	if (HAL_UARTEx_SetTxFifoThreshold(&hlpuart1, UART_TXFIFO_THRESHOLD_1_8) != HAL_OK) {
		Error_Handler();
	}
	if (HAL_UARTEx_SetRxFifoThreshold(&hlpuart1, UART_RXFIFO_THRESHOLD_1_8) != HAL_OK) {
		Error_Handler();
	}
	if (HAL_UARTEx_DisableFifoMode(&hlpuart1) != HAL_OK) {
		Error_Handler();
	}
}

static void MX_TIM2_Init(void)
{
	TIM_ClockConfigTypeDef sClockSourceConfig = {0};
	TIM_MasterConfigTypeDef sMasterConfig = {0};
	htim2.Instance = TIM2;
	htim2.Init.Prescaler = 0;
	htim2.Init.CounterMode = TIM_COUNTERMODE_UP;
	htim2.Init.Period = 1699;
	htim2.Init.ClockDivision = TIM_CLOCKDIVISION_DIV1;
	htim2.Init.AutoReloadPreload = TIM_AUTORELOAD_PRELOAD_ENABLE;
	if (HAL_TIM_Base_Init(&htim2) != HAL_OK) {
		Error_Handler();
	}
	sClockSourceConfig.ClockSource = TIM_CLOCKSOURCE_INTERNAL;
	if (HAL_TIM_ConfigClockSource(&htim2, &sClockSourceConfig) != HAL_OK) {
		Error_Handler();
	}
	sMasterConfig.MasterOutputTrigger = TIM_TRGO_RESET;
	sMasterConfig.MasterSlaveMode = TIM_MASTERSLAVEMODE_DISABLE;
	if (HAL_TIMEx_MasterConfigSynchronization(&htim2, &sMasterConfig) != HAL_OK) {
		Error_Handler();
	}
}

static void MX_TIM3_Init(void)
{
	TIM_ClockConfigTypeDef sClockSourceConfig = {0};
	TIM_MasterConfigTypeDef sMasterConfig = {0};
	htim3.Instance = TIM3;
	htim3.Init.Prescaler = 0;
	htim3.Init.CounterMode = TIM_COUNTERMODE_UP;
	htim3.Init.Period = 11067;
	htim3.Init.ClockDivision = TIM_CLOCKDIVISION_DIV1;
	htim3.Init.AutoReloadPreload = TIM_AUTORELOAD_PRELOAD_ENABLE;
	if (HAL_TIM_Base_Init(&htim3) != HAL_OK) {
		Error_Handler();
	}
	sClockSourceConfig.ClockSource = TIM_CLOCKSOURCE_INTERNAL;
	if (HAL_TIM_ConfigClockSource(&htim3, &sClockSourceConfig) != HAL_OK) {
		Error_Handler();
	}
	sMasterConfig.MasterOutputTrigger = TIM_TRGO_UPDATE;
	sMasterConfig.MasterSlaveMode = TIM_MASTERSLAVEMODE_DISABLE;
	if (HAL_TIMEx_MasterConfigSynchronization(&htim3, &sMasterConfig) != HAL_OK) {
		Error_Handler();
	}
}

static void MX_TIM8_Init(void)
{

	TIM_ClockConfigTypeDef sClockSourceConfig = {0};
	TIM_MasterConfigTypeDef sMasterConfig = {0};

	htim8.Instance = TIM8;
	htim8.Init.Prescaler = 0;
	htim8.Init.CounterMode = TIM_COUNTERMODE_UP;
	htim8.Init.Period = 11067;
	htim8.Init.ClockDivision = TIM_CLOCKDIVISION_DIV1;
	htim8.Init.RepetitionCounter = 0;
	htim8.Init.AutoReloadPreload = TIM_AUTORELOAD_PRELOAD_ENABLE;
	if (HAL_TIM_Base_Init(&htim8) != HAL_OK) {
		Error_Handler();
	}
	sClockSourceConfig.ClockSource = TIM_CLOCKSOURCE_INTERNAL;
	if (HAL_TIM_ConfigClockSource(&htim8, &sClockSourceConfig) != HAL_OK) {
		Error_Handler();
	}
	sMasterConfig.MasterOutputTrigger = TIM_TRGO_UPDATE;
	sMasterConfig.MasterOutputTrigger2 = TIM_TRGO2_RESET;
	sMasterConfig.MasterSlaveMode = TIM_MASTERSLAVEMODE_DISABLE;
	if (HAL_TIMEx_MasterConfigSynchronization(&htim8, &sMasterConfig) != HAL_OK) {
		Error_Handler();
	}
}

static void MX_DMA_Init(void)
{

	/* DMA controller clock enable */
	__HAL_RCC_DMAMUX1_CLK_ENABLE();
	__HAL_RCC_DMA1_CLK_ENABLE();

	HAL_NVIC_SetPriority(DMA1_Channel1_IRQn, 5, 0);
	HAL_NVIC_EnableIRQ(DMA1_Channel1_IRQn);
	/* DMA1_Channel2_IRQn interrupt configuration */
	HAL_NVIC_SetPriority(DMA1_Channel2_IRQn, 5, 0);
	HAL_NVIC_EnableIRQ(DMA1_Channel2_IRQn);
}

static void MX_GPIO_Init(void)
{
	GPIO_InitTypeDef GPIO_InitStruct = {0};

	__HAL_RCC_GPIOC_CLK_ENABLE();
	__HAL_RCC_GPIOF_CLK_ENABLE();
	__HAL_RCC_GPIOA_CLK_ENABLE();

	HAL_NVIC_SetPriority(EXTI15_10_IRQn, 5, 0);
	HAL_NVIC_EnableIRQ(EXTI15_10_IRQn);
}

extern unsigned int ulHighFrequencyTimerTicks;

void HAL_TIM_PeriodElapsedCallback(TIM_HandleTypeDef *htim)
{
	/* USER CODE BEGIN Callback 0 */

	/* USER CODE END Callback 0 */
	if (htim->Instance == TIM1) {
		HAL_IncTick();
	}
	/* USER CODE BEGIN Callback 1 */
	if (htim->Instance == TIM2) {
		ulHighFrequencyTimerTicks++;
	}
	/* USER CODE END Callback 1 */
}
```

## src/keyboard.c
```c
#include "keyboard.h"

static const struct button button0 = {
	.spec = GPIO_DT_SPEC_GET_OR(SW0_NODE, gpios, {0}),
	.num = 0,
};
static struct gpio_callback buttonCbData;
static struct k_work_delayable cooldown_work;

static void button_event_handler()
{
	printk("Botão Pressionado\n");
}

static void cooldown_expired(struct k_work *work)
{
    ARG_UNUSED(work);
    gpio_pin_get_dt(&button0.spec);
    button_event_handler();
}

static void button_press_callback(const struct device *dev, struct gpio_callback *cb, uint32_t pins)
{
	k_work_reschedule(&cooldown_work, K_MSEC(100));
}

int keyboard(const struct button *button)
{
	const struct gpio_dt_spec *spec = &button->spec;
	int ret;

	// Verificar se o botão está pronto para uso
	if (!device_is_ready(spec->port)) {
		LOG_INF("Erro: Botão %s não está pronto\n", spec->port->name);
		return 0;
	}

	// Configuração do pino
	ret = gpio_pin_configure_dt(spec, GPIO_INPUT);
	if (ret != 0) {
		LOG_INF("Erro %d: Falha ao configurar o Botão %s no pino %d\n", ret,
			spec->port->name, spec->pin);
		return 0;
	}

	// Configuração da interrupção do botão
	ret = gpio_pin_interrupt_configure_dt(spec, GPIO_INT_EDGE_TO_ACTIVE);

	if (ret != 0) {
		LOG_INF("Erro %d: Falha ao configurar a interrupção do Botão %s no pino %d\n", ret,
			spec->port->name, spec->pin);
		return 0;
	}

	gpio_init_callback(&buttonCbData, button_press_callback, BIT(spec->pin));
	gpio_add_callback(spec->port, &buttonCbData);
	k_work_init_delayable(&cooldown_work, cooldown_expired);
	LOG_INF("Botão configurado na porta %s no pino %d\n", spec->port->name, spec->pin);

    while(1) {
		k_sleep(K_MSEC(SLEEP_TIME_MS));
	}
}

void keyboard0(void)
{
	keyboard(&button0);
}

K_THREAD_DEFINE(keyboard_task, STACKSIZE, keyboard0, NULL, NULL, NULL, PRIORITY, 0, 0);
```

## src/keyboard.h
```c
#include "main.h"

#define SW0_NODE  DT_ALIAS(sw0)

#if !DT_NODE_HAS_STATUS(SW0_NODE, okay)
#error "Unsupported board: sw0 devicetree alias is not defined"
#endif

struct button {
	struct gpio_dt_spec spec;
	uint8_t num;
};
```
